# SERDES_10G0 register map
Vendor: Texas Instruments
Peripheral module from a debugger description file (folder J721S2).
Registers are 32-bit, read-write, reset 0x0 unless marked. A register's access mark holds for its fields unless they carry their own. Offsets are as the file gives them; lines under a group give offsets from that group; [hi:lo] are bit positions; {n}, {i} and the like mark numbered series; 'fields as' and 'values as' point back to an identical list; <NAME> marks a mode.

## SERDES_10G0 (part 1 of 5)
0x40 WIZ16B8M4CT2_CMN_SSM_BANDGAP_TMR__CMN_SSM_SM_CTRL reset 0x10000 — Startup state machine control register
  [20:16] CMN_SSM_BANDGAP_TMR_4_0 — Bandgap enable state timer value : Value used for the timer when the startup state machine is in the bandgap enable state. This timer delay is specified as the number of reference clocks to count. This value creates a delay of 40 nSec. Note, when exiting common suspend mode, a total of 1000 nSec is required for the bandgap to be enabled. This total delay is what is ultimately used to determine what the delay needs to be in the bandgap enable state. Of this total time, 960 nSec of this time is accounted for in the suspend recovery state. The remainder is accounted for here.
0x44 WIZ16B8M4CT2_CMN_SSM_BIAS_TMR reset 0x19 — Bias enable timer register
  [6:0] CMN_SSM_BIAS_TMR_6_0 — Bias enable state timer value : Value used for the timer when the startup state machine is in the bias enable state. This timer delay is specified as the number of reference clocks to count. This value creates a delay of 1 uSec.
0x50 WIZ16B8M4CT2_CMN_PLLSM0_PLLEN_TMR__CMN_PLLSM0_SM_CTRL reset 0x40000 — PLL 0 control state machine control register
  [19:16] CMN_PLLSM0_PLLEN_TMR_3_0 — PLL enable state timer value : Value used for the timer when the startup state machine is in the PLL enable state. This timer delay is specified as the number of reference clocks to count.
0x54 WIZ16B8M4CT2_CMN_PLLSM0_PLLVREF_TMR__CMN_PLLSM0_PLLPRE_TMR reset 0x32 — PLL 0 pre-charge timer register
  [7:0] CMN_PLLSM0_PLLPRE_TMR_7_0 — PLL pre-charge state timer value : Value used for the timer when the startup state machine is in the PLL pre-charge state. This timer delay is specified as the number of reference clocks to count. This value creates a delay of 2 uSec.
0x58 WIZ16B8M4CT2_CMN_PLLSM0_PLLCLKDIS_TMR__CMN_PLLSM0_PLLLOCK_TMR reset 0xD1 — PLL 0 lock delay timer register
  [9:0] CMN_PLLSM0_PLLLOCK_TMR_9_0 — PLL lock delay state timer value : Value used for the timer when the startup state machine is in the PLL lock delay state. This timer delay is specified as the number of reference clocks to count.
0x60 WIZ16B8M4CT2_CMN_PLLSM1_PLLEN_TMR__CMN_PLLSM1_SM_CTRL reset 0x40000 — PLL 1 control state machine control register
  [19:16] CMN_PLLSM1_PLLEN_TMR_3_0 — PLL enable state timer value : Value used for the timer when the startup state machine is in the PLL enable state. This timer delay is specified as the number of reference clocks to count.
0x64 WIZ16B8M4CT2_CMN_PLLSM1_PLLVREF_TMR__CMN_PLLSM1_PLLPRE_TMR reset 0x32 — PLL 1 pre-charge timer register
  [7:0] CMN_PLLSM1_PLLPRE_TMR_7_0 — PLL pre-charge state timer value : Value used for the timer when the startup state machine is in the PLL pre-charge state. This timer delay is specified as the number of reference clocks to count.
0x68 WIZ16B8M4CT2_CMN_PLLSM1_PLLCLKDIS_TMR__CMN_PLLSM1_PLLLOCK_TMR reset 0xD1 — PLL 1 lock delay timer register
  [9:0] CMN_PLLSM1_PLLLOCK_TMR_9_0 — PLL lock delay state timer value : Value used for the timer when the startup state machine is in the PLL lock delay state. This timer delay is specified as the number of reference clocks to count.
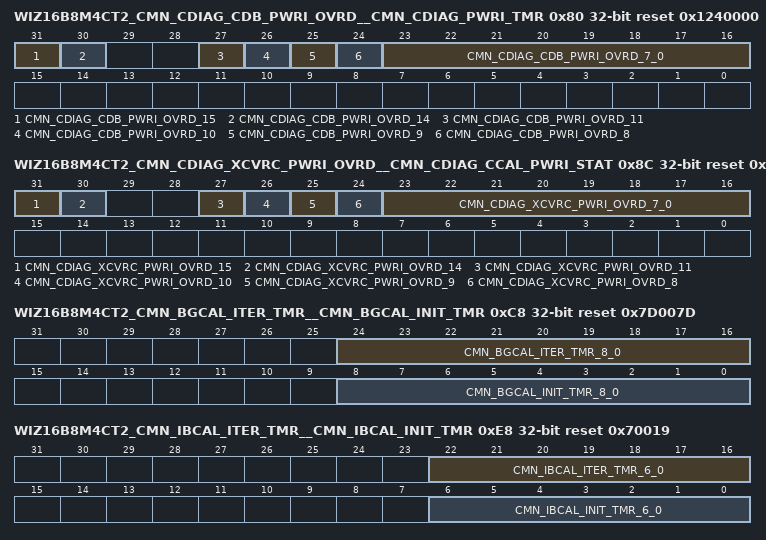
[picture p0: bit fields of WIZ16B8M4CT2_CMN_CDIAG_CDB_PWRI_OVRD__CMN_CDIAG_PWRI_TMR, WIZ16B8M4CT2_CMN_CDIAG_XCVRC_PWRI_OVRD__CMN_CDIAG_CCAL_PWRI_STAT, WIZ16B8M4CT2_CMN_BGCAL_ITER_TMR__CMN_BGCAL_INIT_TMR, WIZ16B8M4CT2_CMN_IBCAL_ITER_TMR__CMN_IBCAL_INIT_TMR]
0x80 WIZ16B8M4CT2_CMN_CDIAG_CDB_PWRI_OVRD__CMN_CDIAG_PWRI_TMR access per field reset 0x1240000 — Common power island control timer register
  [31] CMN_CDIAG_CDB_PWRI_OVRD_15 rw — Power island controller input override enable: When enabled, the power island control state machine input override bits in this register will drive the power island control state machine directly, and override any control from other state machines in the macro. Note that this bit must never change state in the same register write that any of the override bits it controls in this register are changed. 1'b0: Override disabled 1'b1: Override enabled
  [30] CMN_CDIAG_CDB_PWRI_OVRD_14 rw — Power island controller output override enable: When enabled, the power island control state machine output override bits in this register will drive the power island control state machine outputs, and override any control from power island control state machine. Note that this bit must never change state in the same register write that any of the override bits it controls in this register are changed. 1'b0: Override disabled 1'b1: Override enabled
  [27] CMN_CDIAG_CDB_PWRI_OVRD_11 rw — Power suspend request override: When enabled, this bit will override the power_suspend_req input of the power island control state machine. Note that, whenever changing the state of this bit, no other CDB register access should be initiated for 1 uSec, to keep the CDB clock off while the power island state change transition is in progress.
  [26] CMN_CDIAG_CDB_PWRI_OVRD_10 ro — Power suspend acknowledge: This is the current state of the power_suspend_ack output from the power island control state machine. Note that this bit will always be set to 1'b1 after the power island is enabled, as a function of the power island controller input override enable bit in this register.
  [25] CMN_CDIAG_CDB_PWRI_OVRD_9 rw — Power recover request override: When enabled, this bit will override the power_recover_req input of the power island control state machine. Note that, whenever changing the state of this bit, no other CDB register access should be initiated for 1 uSec, to keep the CDB clock off while the power island state change transition is in progress.
  [24] CMN_CDIAG_CDB_PWRI_OVRD_8 ro — Power recover acknowledge: This is the current state of the power_recover_ack output from the power island control state machine. Note that this bit will always be set to 1'b1 after the power island is enabled, as a function of the power island controller input override enable bit in this register.
  [23:16] CMN_CDIAG_CDB_PWRI_OVRD_7_0 rw — Power island controller output override: When enabled, the bits in this field will override the output signals from the power island control state machine. The following are the power island control state machine output signals, and the bits in this field that they are associated with. Bit 7: state_sandh Bit 6: state_ret_save Bit 5: state_ret_restore (active low) Bit 4: power_en_ph_1 Bit 3: power_en_ph_2 Bit 2: power_isolation Bit 1: power_por_reset_n Bit 0: power_rstr_reset_n The default value of the bits in this register are such that the power island is not forced to be switched on when the power island controller output override enable bit in this register is enabled. When using this register to switch this power island on and off, the bits in this field are required to change in a specific order with individual register writes. The writes must happen in the order specified below. 8'b00100100 : Power island is not being forced on 8'b10100100 8'b10110100 8'b10111100 8'b10111111 8'b10111011 8'b00111011 : Power island is being forced on 8'b10111011 8'b10111111 8'b11111111 8'b10111111 8'b10111110 8'b10100110 : Power island is being forced off, and in state retention 8'b10110110 8'b10111110 8'b10111111 8'b10011111 8'b10111111 8'b10111011 8'b00111011 : Power island is being forced on, with state restored Note: When using this output override option in conditions when the reference clock is off, the CDB registers on the power island will only be readable, and latency will be much longer. The reason for this is the reference clock is normally used to synchronize control functions associated with this power island. Therefore these control functions will not proceed as they would in normal operation. This results in writes not being capable, and reads completing under the control of the watchdog timer.
0x8C WIZ16B8M4CT2_CMN_CDIAG_XCVRC_PWRI_OVRD__CMN_CDIAG_CCAL_PWRI_STAT access per field reset 0x4240000 — Common common calibration power island control status register
  [31] CMN_CDIAG_XCVRC_PWRI_OVRD_15 rw — Power island controller input override enable: When enabled, the power island control state machine input override bits in this register will drive the power island control state machine directly, and override any control from other state machines in the macro. Note that this bit must never change state in the same register write that any of the override bits it controls in this register are changed. 1'b0: Override disabled 1'b1: Override enabled
  [30] CMN_CDIAG_XCVRC_PWRI_OVRD_14 rw — Power island controller output override enable: When enabled, the power island control state machine output override bits in this register will drive the power island control state machine outputs, and override any control from power island control state machine. Note that this bit must never change state in the same register write that any of the override bits it controls in this register are changed. 1'b0: Override disabled 1'b1: Override enabled
  [27] CMN_CDIAG_XCVRC_PWRI_OVRD_11 rw — Power suspend request override: When enabled, this bit will override the power_suspend_req input of the power island control state machine.
  [26] CMN_CDIAG_XCVRC_PWRI_OVRD_10 ro — Power suspend acknowledge: This is the current state of the power_suspend_ack output from the power island control state machine. Note that this bit will always be set to 1'b1 after the power island is enabled, as a function of the power island controller input override enable bit in this register.
  [25] CMN_CDIAG_XCVRC_PWRI_OVRD_9 rw — Power recover request override: When enabled, this bit will override the power_recover_req input of the power island control state machine.
  [24] CMN_CDIAG_XCVRC_PWRI_OVRD_8 ro — Power recover acknowledge: This is the current state of the power_recover_ack output from the power island control state machine. Note that this bit will always be set to 1'b1 after the power island is enabled, as a function of the power island controller input override enable bit in this register.
  [23:16] CMN_CDIAG_XCVRC_PWRI_OVRD_7_0 rw — Power island controller output override: When enabled, the bits in this field will override the output signals from the power island control state machine. The following are the power island control state machine output signals, and the bits in this field that they are associated with. Bit 7: state_sandh Bit 6: state_ret_save Bit 5: state_ret_restore (active low) Bit 4: power_en_ph_1 Bit 3: power_en_ph_2 Bit 2: power_isolation Bit 1: power_por_reset_n Bit 0: power_rstr_reset_n The default value of the bits in this register are such that the power island is not forced to be switched on when the power island controller output override enable bit in this register is enabled. When using this register to switch this power island on and off, the bits in this field are required to change in a specific order with individual register writes. The writes must happen in the order specified below. 8'b00100100 : Power island is not being forced on 8'b10100100 8'b10110100 8'b10111100 8'b10111111 8'b10111011 8'b00111011 : Power island is being forced on 8'b10111011 8'b10111111 8'b11111111 8'b10111111 8'b10111110 8'b10100110 : Power island is being forced off, and in state retention 8'b10110110 8'b10111110 8'b10111111 8'b10011111 8'b10111111 8'b10111011 8'b00111011 : Power island is being forced on, with state restored
0xC8 WIZ16B8M4CT2_CMN_BGCAL_ITER_TMR__CMN_BGCAL_INIT_TMR reset 0x7D007D — Bandgap calibration initialization timer register
  [24:16] CMN_BGCAL_ITER_TMR_8_0 — Iteration wait timer value: This is the number of cmn_ref_clk clocks to wait between when a value is placed on the bandgap calibration signals going to the analog, and when the comparator value coming from the analog circuits can be checked. Note that this results in the minimum number of cmn_ref_clk clocks required to wait 5 uSec. Note that this should never be set to a value of less than 3.
  [8:0] CMN_BGCAL_INIT_TMR_8_0 — Initialization wait timer value: This is the number of cmn_ref_clk clocks to wait between when the analog bandgap calibration circuits are enabled, and when the first values are placed on the bandgap calibration signals going to the analog. Note that this results in the minimum number of cmn_ref_clk clocks required to wait 5 uSec. Note that this should never be set to a value of less than 1.
0xE8 WIZ16B8M4CT2_CMN_IBCAL_ITER_TMR__CMN_IBCAL_INIT_TMR reset 0x70019 — External bias current calibration initialization timer register
  [22:16] CMN_IBCAL_ITER_TMR_6_0 — Iteration wait timer value: This is the number of cmn_ref_clk clocks to wait between when a value is placed on the calibration selection bus going to the analog, and when the comparator value coming from the analog circuits can be checked. Note that this should never be set to a value of less than 3.
  [6:0] CMN_IBCAL_INIT_TMR_6_0 — Initialization wait timer value: This is the number of cmn_ref_clk clocks to wait between when the analog calibration circuits are enabled, and when the first calibration selection value is placed on the calibration code bus, going to the analog. Note that this results in the minimum number of cmn_ref_clk clocks required to wait 1 uSec. Note that this should never be set to a value of less than 1.
0x104 WIZ16B8M4CT2_CMN_PLL0_VCOCAL_OVRD__CMN_PLL0_VCOCAL_TCTRL reset 0x4 — PLL 0 VCO calibration timer control register
  [2:0] CMN_PLL0_VCOCAL_TCTRL_2_0 — VCO calibration initial time scale control: This field specifies the calibration start time scaling factor applied to the VCO calibration when running the initial step size for the calibration code if not set to 1. Setting this value to a value other than 1 will reduce the calibration measurement time by the amount specified below. Then when the final calibration steps are made the full calibration time will be used to get the appropriate amount of resolution. 3'b000 : Div 1 3'b001 : Div 2 3'b010 : Div 4 3'b011 : Div 8 3'b100 : Div 16 3'b101 : Div 32 3'b110 : Div 64 3'b111 : Div 128
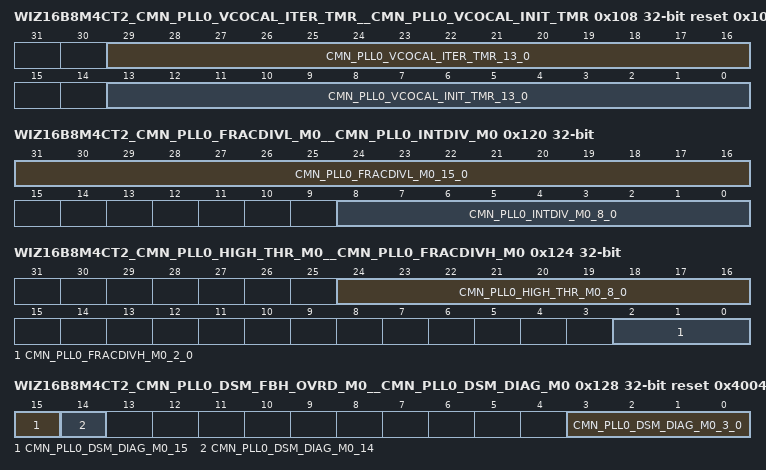
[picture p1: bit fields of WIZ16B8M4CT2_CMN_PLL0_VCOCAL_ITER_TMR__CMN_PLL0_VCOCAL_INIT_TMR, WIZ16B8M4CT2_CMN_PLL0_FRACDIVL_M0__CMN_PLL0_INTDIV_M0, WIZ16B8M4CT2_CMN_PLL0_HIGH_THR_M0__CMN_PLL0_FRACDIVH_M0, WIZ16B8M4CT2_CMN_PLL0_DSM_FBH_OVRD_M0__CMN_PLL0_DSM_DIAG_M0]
0x108 WIZ16B8M4CT2_CMN_PLL0_VCOCAL_ITER_TMR__CMN_PLL0_VCOCAL_INIT_TMR reset 0x1003E8 — PLL 0 VCO calibration initialization timer register
  [29:16] CMN_PLL0_VCOCAL_ITER_TMR_13_0 — Iteration wait timer value: This is the number of clocks to wait between when a calibration code is driven to the analog, and when the clock rates are measured.
  [13:0] CMN_PLL0_VCOCAL_INIT_TMR_13_0 — Initialization wait timer value: This is the number of clocks to wait between when the analog VCO calibration circuits are enabled, and when the first calibration code is driven to the analog. Note that this results in the minimum number of cmn_ref_clk clocks required to wait 10 uSec.
0x10C WIZ16B8M4CT2_CMN_PLL0_VCOCAL_REFTIM_START reset 0xC5F — PLL 0 VCO calibration reference clock timer start value register
  [13:0] CMN_PLL0_VCOCAL_REFTIM_START_13_0 — PLL VCO calibration reference clock timer start value : This is the value that is loaded into the reference clock timer as the starting point for that timer, when running VCO calibration. The value in this field must correspond to a time that is approximately one full spread spectrum cycle long (31.67 uSec) Note that the actual number of clocks counted is one larger than what is specified by this field.
0x110 WIZ16B8M4CT2_CMN_PLL0_VCOCAL_PLLCNT_START reset 0xC5F — PLL 0 VCO calibration PLL clock counter start value register
  [13:0] CMN_PLL0_VCOCAL_PLLCNT_START_13_0 — PLL VCO calibration PLL clock counter start value : This is the value that is loaded into the PLL clock counter as the starting point for that counter, when running VCO calibration. When programming this register, it is important to understand how the frequency of the cmnda_pll0_fb_divider_clk is calculated relative to the reference clock. This is described in section 10.4 Dual VCO PLL on page 420. Note that the actual number of clocks counted is one larger than what is specified by this field.
0x120 WIZ16B8M4CT2_CMN_PLL0_FRACDIVL_M0__CMN_PLL0_INTDIV_M0 — PLL 0 feedback divider integer register mode 0
  [31:16] CMN_PLL0_FRACDIVL_M0_15_0 — pll_fb_div_fractional: Value of the pll_fb_div_fractional[15:0] signal.
  [8:0] CMN_PLL0_INTDIV_M0_8_0 — pll_fb_div_integer value: Value of the pll_fb_div_integer signal.
0x124 WIZ16B8M4CT2_CMN_PLL0_HIGH_THR_M0__CMN_PLL0_FRACDIVH_M0 — PLL 0 feedback divider fractional high register mode 0
  [24:16] CMN_PLL0_HIGH_THR_M0_8_0 — pll_fb_div_high_theshold: Value of the pll_fb_div_high_threshold signal. The value of this register should be 2/3 the value of the combined integer and fractional divider values, and rounded up to the next even number.
  [2:0] CMN_PLL0_FRACDIVH_M0_2_0 — pll_fb_div_fractional: Value of the pll_fb_div_fractional[18:16] signal.
0x128 WIZ16B8M4CT2_CMN_PLL0_DSM_FBH_OVRD_M0__CMN_PLL0_DSM_DIAG_M0 reset 0x4004 — PLL 0 delta sigma modulator diagnostics register mode 0
  [15] CMN_PLL0_DSM_DIAG_M0_15 — Delta sigma bypass enable: When set to 1'b1, the delta sigma modulator will be bypassed, and the output will be the value specified for the internal pll_fb_div_integer signal.
  [14] CMN_PLL0_DSM_DIAG_M0_14 — PLL feedback divider override enable : When active (1'b1), the feedback divider low and high override values in the PLL 0 delta sigma modulator feedback divider value high override register mode 0 on page 114 and PLL 0 delta sigma modulator feedback divider value low override register mode 0 on page 114 registers will be used to override the feedback divider values driven to the analog.
  [3:0] CMN_PLL0_DSM_DIAG_M0_3_0 — PLL feedback divider latency adjustment: This signal specifies a value to be subtracted from the feedback divider settings before they are output on the cmnda_pll0_fb_div_high and cmnda_pll0_fb_div_low signals.
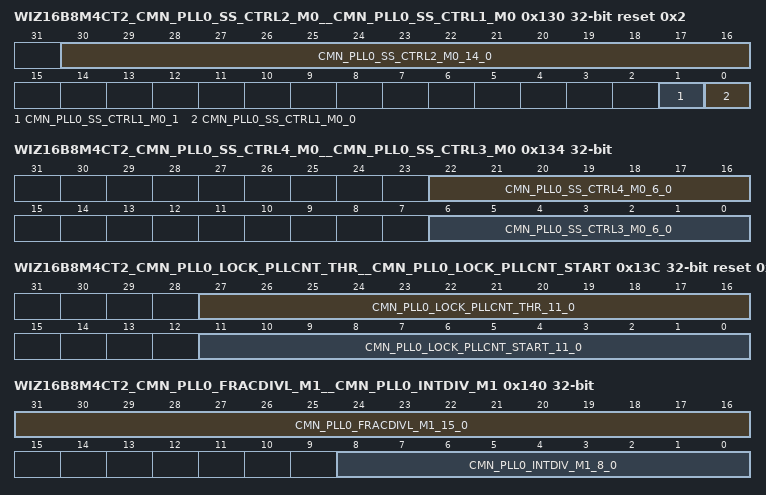
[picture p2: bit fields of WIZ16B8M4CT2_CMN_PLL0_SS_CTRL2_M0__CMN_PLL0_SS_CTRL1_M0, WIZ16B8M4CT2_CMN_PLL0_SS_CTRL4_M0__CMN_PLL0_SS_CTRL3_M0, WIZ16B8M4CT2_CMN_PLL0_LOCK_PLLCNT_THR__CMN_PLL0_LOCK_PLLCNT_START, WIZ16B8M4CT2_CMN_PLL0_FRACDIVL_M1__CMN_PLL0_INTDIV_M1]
0x130 WIZ16B8M4CT2_CMN_PLL0_SS_CTRL2_M0__CMN_PLL0_SS_CTRL1_M0 reset 0x2 — PLL 0 spread spectrum control register 1 mode 0
  [30:16] CMN_PLL0_SS_CTRL2_M0_14_0 — Amplitude step size: Value of the amplitude_step_size pin on the spread spectrum waveform generator. Note that this field should not be set to 0 when spread spectrum is enabled.
  [1] CMN_PLL0_SS_CTRL1_M0_1 — Spread spectrum waveform generator disable: Setting this bit to a 1'b1 will disable the spread spectrum waveform generator.
  [0] CMN_PLL0_SS_CTRL1_M0_0 — Spread spectrum enable during VCO calibration : Setting this bit to a 1'b1 will enable the spread spectrum function while VCO calibration is taking place.
0x134 WIZ16B8M4CT2_CMN_PLL0_SS_CTRL4_M0__CMN_PLL0_SS_CTRL3_M0 — PLL 0 spread spectrum control register 3 mode 0
  [22:16] CMN_PLL0_SS_CTRL4_M0_6_0 — Time step size: Value for the time_step_size pin on the spread spectrum waveform generator. Note that this field should not be set to 0 when spread spectrum is enabled.
  [6:0] CMN_PLL0_SS_CTRL3_M0_6_0 — Number of steps: Value of the num_steps pin on the spread spectrum waveform generator. Note that this field should not be set to 0 when spread spectrum is enabled.
0x138 WIZ16B8M4CT2_CMN_PLL0_LOCK_REFCNT_IDLE__CMN_PLL0_LOCK_REFCNT_START reset 0xC8 — PLL 0 lock reference counter start value register
  [11:0] CMN_PLL0_LOCK_REFCNT_START_11_0 — PLL lock reference counter start value : This is the value that is loaded into the PLL lock detect reference counter as the starting point for that counter, when checking for PLL lock. Note that the value required here is a function of the PLL feedback divider clock mode and the reference clock frequency. Overview information in regards to this can be found in section 4.2 Reference Clock Related Clocking and Reset on page 296 and section 4.9 Reference Clock Related Clock Rate Summary on page 324. The following bullet points specify the required time the value in this register is required to generate. By default, the value in this register is set for FBR mode with a 100 MHz reference clock. FBR mode and reference clock frequency greater than or equal to 100 MHz: 2 uSec FBR mode and reference clock frequency less than 100 MHz: 8 uSec DR mode: 800 nSec
0x13C WIZ16B8M4CT2_CMN_PLL0_LOCK_PLLCNT_THR__CMN_PLL0_LOCK_PLLCNT_START reset 0x300C8 — PLL 0 lock PLL counter start value register
  [27:16] CMN_PLL0_LOCK_PLLCNT_THR_11_0 — PLL lock counter threshold value : This is the value used by the PLL lock detection logic to determine if the PLL has locked. If the two counters in the PLL lock detection logic differ by less than this value, the PLL is considered locked.
  [11:0] CMN_PLL0_LOCK_PLLCNT_START_11_0 — PLL lock PLL counter start value : This is the value that is loaded into the PLL lock detect PLL counter as the starting point for that counter, when checking for PLL lock. The value is the number of PLL feedback divider clock edges that are expected during the time specified by the PLL 0 lock reference counter start value register on page 112. When programming this register, it is important to understand how the frequency of the cmnda_pll0_fb_divider_clk is calculated relative to the reference clock. This is described in section 10.4 Dual VCO PLL on page 420.
0x140 WIZ16B8M4CT2_CMN_PLL0_FRACDIVL_M1__CMN_PLL0_INTDIV_M1 — PLL 0 feedback divider integer register mode 1
  [31:16] CMN_PLL0_FRACDIVL_M1_15_0 — pll_fb_div_fractional: Value of the pll_fb_div_fractional[15:0] signal.
  [8:0] CMN_PLL0_INTDIV_M1_8_0 — pll_fb_div_integer value: Value of the pll_fb_div_integer signal.
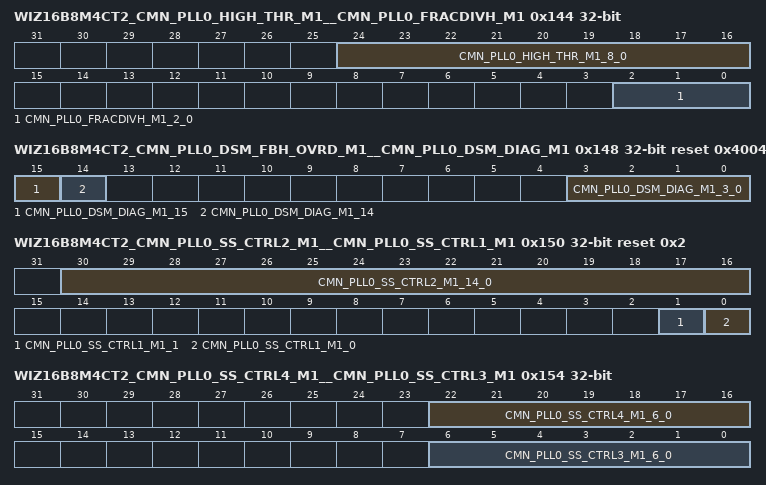
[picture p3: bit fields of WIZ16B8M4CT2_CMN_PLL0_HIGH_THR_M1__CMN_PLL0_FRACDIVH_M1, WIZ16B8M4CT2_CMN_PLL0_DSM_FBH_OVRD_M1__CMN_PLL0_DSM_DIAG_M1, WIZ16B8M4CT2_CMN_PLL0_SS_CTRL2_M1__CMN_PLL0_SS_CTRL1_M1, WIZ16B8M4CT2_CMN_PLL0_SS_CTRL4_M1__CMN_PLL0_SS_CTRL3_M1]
0x144 WIZ16B8M4CT2_CMN_PLL0_HIGH_THR_M1__CMN_PLL0_FRACDIVH_M1 — PLL 0 feedback divider fractional high register mode 1
  [24:16] CMN_PLL0_HIGH_THR_M1_8_0 — pll_fb_div_high_theshold: Value of the pll_fb_div_high_threshold signal. The value of this register should be 2/3 the value of the combined integer and fractional divider values, and rounded up to the next even number.
  [2:0] CMN_PLL0_FRACDIVH_M1_2_0 — pll_fb_div_fractional: Value of the pll_fb_div_fractional[18:16] signal.
0x148 WIZ16B8M4CT2_CMN_PLL0_DSM_FBH_OVRD_M1__CMN_PLL0_DSM_DIAG_M1 reset 0x4004 — PLL 0 delta sigma modulator diagnostics register mode 1
  [15] CMN_PLL0_DSM_DIAG_M1_15 — Delta sigma bypass enable: When set to 1'b1, the delta sigma modulator will be bypassed, and the output will be the value specified for the internal pll_fb_div_integer signal.
  [14] CMN_PLL0_DSM_DIAG_M1_14 — PLL feedback divider override enable : When active (1'b1), the feedback divider low and high override values in the PLL 0 delta sigma modulator feedback divider value high override register mode 0 on page 114 and PLL 0 delta sigma modulator feedback divider value low override register mode 0 on page 114 registers will be used to override the feedback divider values driven to the analog.
  [3:0] CMN_PLL0_DSM_DIAG_M1_3_0 — PLL feedback divider latency adjustment: This signal specifies a value to be subtracted from the feedback divider settings before they are output on the cmnda_pll0_fb_div_high and cmnda_pll0_fb_div_low signals.
0x150 WIZ16B8M4CT2_CMN_PLL0_SS_CTRL2_M1__CMN_PLL0_SS_CTRL1_M1 reset 0x2 — PLL 0 spread spectrum control register 1 mode 1
  [30:16] CMN_PLL0_SS_CTRL2_M1_14_0 — Amplitude step size: Value of the amplitude_step_size pin on the spread spectrum waveform generator. Note that this field should not be set to 0 when spread spectrum is enabled.
  [1] CMN_PLL0_SS_CTRL1_M1_1 — Spread spectrum waveform generator disable: Setting this bit to a 1'b1 will disable the spread spectrum waveform generator.
  [0] CMN_PLL0_SS_CTRL1_M1_0 — Spread spectrum enable during VCO calibration : Setting this bit to a 1'b1 will enable the spread spectrum function while VCO calibration is taking place.
0x154 WIZ16B8M4CT2_CMN_PLL0_SS_CTRL4_M1__CMN_PLL0_SS_CTRL3_M1 — PLL 0 spread spectrum control register 3 mode 1
  [22:16] CMN_PLL0_SS_CTRL4_M1_6_0 — Time step size: Value for the time_step_size pin on the spread spectrum waveform generator. Note that this field should not be set to 0 when spread spectrum is enabled.
  [6:0] CMN_PLL0_SS_CTRL3_M1_6_0 — Number of steps: Value of the num_steps pin on the spread spectrum waveform generator. Note that this field should not be set to 0 when spread spectrum is enabled.
0x184 WIZ16B8M4CT2_CMN_PLL1_VCOCAL_OVRD__CMN_PLL1_VCOCAL_TCTRL reset 0x4 — PLL 1 VCO calibration timer control register
  [2:0] CMN_PLL1_VCOCAL_TCTRL_2_0 — VCO calibration initial time scale control: This field specifies the calibration start time scaling factor applied to the VCO calibration when running the initial step size for the calibration code if not set to 1. Setting this value to a value other than 1 will reduce the calibration measurement time by the amount specified below. Then when the final calibration steps are made the full calibration time will be used to get the appropriate amount of resolution. 3'b000 : Div 1 3'b001 : Div 2 3'b010 : Div 4 3'b011 : Div 8 3'b100 : Div 16 3'b101 : Div 32 3'b110 : Div 64 3'b111 : Div 128
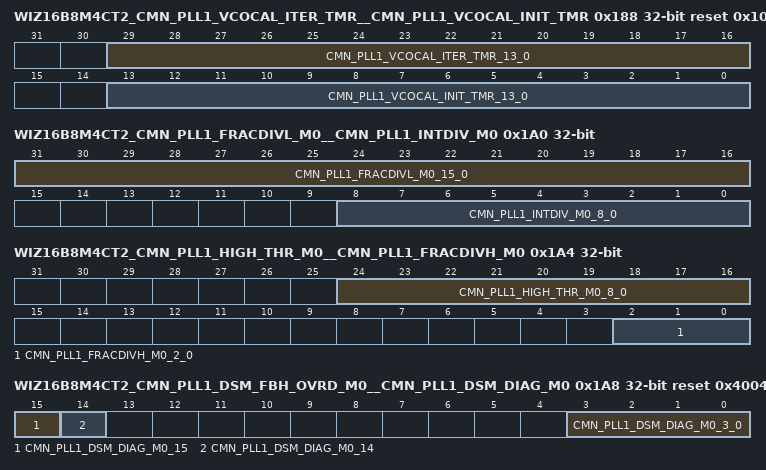
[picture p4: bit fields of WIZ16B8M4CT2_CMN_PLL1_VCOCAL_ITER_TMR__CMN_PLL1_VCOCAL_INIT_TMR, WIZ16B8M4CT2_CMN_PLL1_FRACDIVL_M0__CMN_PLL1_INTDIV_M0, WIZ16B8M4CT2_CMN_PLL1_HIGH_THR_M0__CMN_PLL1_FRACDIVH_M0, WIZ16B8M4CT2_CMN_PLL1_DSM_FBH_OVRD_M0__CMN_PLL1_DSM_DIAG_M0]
0x188 WIZ16B8M4CT2_CMN_PLL1_VCOCAL_ITER_TMR__CMN_PLL1_VCOCAL_INIT_TMR reset 0x1003E8 — PLL 1 VCO calibration initialization timer register
  [29:16] CMN_PLL1_VCOCAL_ITER_TMR_13_0 — Iteration wait timer value: This is the number of clocks to wait between when a calibration code is driven to the analog, and when the clock rates are measured.
  [13:0] CMN_PLL1_VCOCAL_INIT_TMR_13_0 — Initialization wait timer value: This is the number of clocks to wait between when the analog VCO calibration circuits are enabled, and when the first calibration code is driven to the analog. Note that the reset value for this field corresponds to a time of 10 uSec.
0x18C WIZ16B8M4CT2_CMN_PLL1_VCOCAL_REFTIM_START reset 0xC5F — PLL 1 VCO calibration reference clock timer start value register
  [13:0] CMN_PLL1_VCOCAL_REFTIM_START_13_0 — PLL VCO calibration reference clock timer start value : This is the value that is loaded into the reference clock timer as the starting point for that timer, when running VCO calibration. The value in this field must correspond to a time that is approximately one full spread spectrum cycle long (31.67 uSec) Note that the actual number of clocks counted is one larger than what is specified by this field.
0x190 WIZ16B8M4CT2_CMN_PLL1_VCOCAL_PLLCNT_START reset 0xC5F — PLL 1 VCO calibration PLL clock counter start value register
  [13:0] CMN_PLL1_VCOCAL_PLLCNT_START_13_0 — PLL VCO calibration PLL clock counter start value : This is the value that is loaded into the PLL clock counter as the starting point for that counter, when running VCO calibration. When programming this register, it is important to understand how the frequency of the cmnda_pll0_fb_divider_clk is calculated relative to the reference clock. This is described in section 10.4 Dual VCO PLL on page 420. Note that the actual number of clocks counted is one larger than what is specified by this field.
0x1A0 WIZ16B8M4CT2_CMN_PLL1_FRACDIVL_M0__CMN_PLL1_INTDIV_M0 — PLL 1 feedback divider integer register mode 0
  [31:16] CMN_PLL1_FRACDIVL_M0_15_0 — pll_fb_div_fractional: Value of the pll_fb_div_fractional[15:0] signal.
  [8:0] CMN_PLL1_INTDIV_M0_8_0 — pll_fb_div_integer value: Value of the pll_fb_div_integer signal.
0x1A4 WIZ16B8M4CT2_CMN_PLL1_HIGH_THR_M0__CMN_PLL1_FRACDIVH_M0 — PLL 1 feedback divider fractional high register mode 0
  [24:16] CMN_PLL1_HIGH_THR_M0_8_0 — pll_fb_div_high_theshold: Value of the pll_fb_div_high_threshold signal. The value of this register should be 2/3 the value of the combined integer and fractional divider values, and rounded up to the next even number.
  [2:0] CMN_PLL1_FRACDIVH_M0_2_0 — pll_fb_div_fractional: Value of the pll_fb_div_fractional[18:16] signal.
0x1A8 WIZ16B8M4CT2_CMN_PLL1_DSM_FBH_OVRD_M0__CMN_PLL1_DSM_DIAG_M0 reset 0x4004 — PLL 1 delta sigma modulator diagnostics register mode 0
  [15] CMN_PLL1_DSM_DIAG_M0_15 — Delta sigma bypass enable: When set to 1'b1, the delta sigma modulator will be bypassed, and the output will be the value specified for the internal pll_fb_div_integer signal.
  [14] CMN_PLL1_DSM_DIAG_M0_14 — PLL feedback divider override enable : When active (1'b1), the feedback divider low and high override values in the PLL 1 delta sigma modulator feedback divider value high override register mode 0 on page 123 and PLL 1 delta sigma modulator feedback divider value low override register mode 0 on page 123 registers will be used to override the feedback divider values driven to the analog.
  [3:0] CMN_PLL1_DSM_DIAG_M0_3_0 — PLL feedback divider latency adjustment: This signal specifies a value to be subtracted from the feedback divider settings before they are output on the cmnda_pll1_fb_div_high and cmnda_pll1_fb_div_low signals.
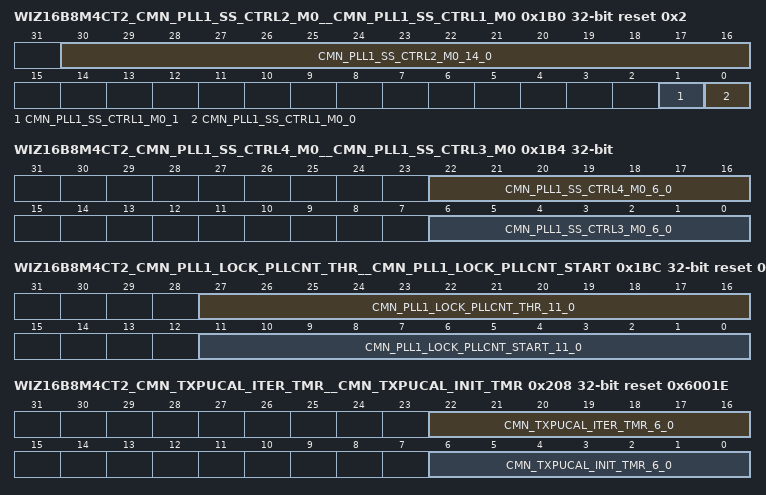
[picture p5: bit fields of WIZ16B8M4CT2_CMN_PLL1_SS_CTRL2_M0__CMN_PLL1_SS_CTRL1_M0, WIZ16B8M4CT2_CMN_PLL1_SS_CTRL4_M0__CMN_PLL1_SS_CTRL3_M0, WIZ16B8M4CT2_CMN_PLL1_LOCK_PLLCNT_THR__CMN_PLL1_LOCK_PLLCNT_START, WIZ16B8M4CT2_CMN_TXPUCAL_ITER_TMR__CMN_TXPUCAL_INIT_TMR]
0x1B0 WIZ16B8M4CT2_CMN_PLL1_SS_CTRL2_M0__CMN_PLL1_SS_CTRL1_M0 reset 0x2 — PLL 1 spread spectrum control register 1 mode 0
  [30:16] CMN_PLL1_SS_CTRL2_M0_14_0 — Amplitude step size: Value of the amplitude_step_size pin on the spread spectrum waveform generator. Note that this field should not be set to 0 when spread spectrum is enabled.
  [1] CMN_PLL1_SS_CTRL1_M0_1 — Spread spectrum waveform generator disable: Setting this bit to a 1'b1 will disable the spread spectrum waveform generator.
  [0] CMN_PLL1_SS_CTRL1_M0_0 — Spread spectrum enable during VCO calibration : Setting this bit to a 1'b1 will enable the spread spectrum function while VCO calibration is taking place.
0x1B4 WIZ16B8M4CT2_CMN_PLL1_SS_CTRL4_M0__CMN_PLL1_SS_CTRL3_M0 — PLL 1 spread spectrum control register 3 mode 0
  [22:16] CMN_PLL1_SS_CTRL4_M0_6_0 — Time step size: Value for the time_step_size pin on the spread spectrum waveform generator. Note that this field should not be set to 0 when spread spectrum is enabled.
  [6:0] CMN_PLL1_SS_CTRL3_M0_6_0 — Number of steps: Value of the num_steps pin on the spread spectrum waveform generator. Note that this field should not be set to 0 when spread spectrum is enabled.
0x1B8 WIZ16B8M4CT2_CMN_PLL1_LOCK_REFCNT_IDLE__CMN_PLL1_LOCK_REFCNT_START reset 0xC8 — PLL 1 lock reference counter start value register
  [11:0] CMN_PLL1_LOCK_REFCNT_START_11_0 — PLL lock reference counter start value : This is the value that is loaded into the PLL lock detect reference counter as the starting point for that counter, when checking for PLL lock. Note that the value required here is a function of the PLL feedback divider clock mode and the reference clock frequency. Overview information in regards to this can be found in section 4.2 Reference Clock Related Clocking and Reset on page 296 and section 4.9 Reference Clock Related Clock Rate Summary on page 324. The following bullet points specify the required time the value in this register is required to generate. By default, the value in this register is set for FBR mode with a 100 MHz reference clock. FBR mode and reference clock frequency greater than or equal to 100 MHz: 2 uSec FBR mode and reference clock frequency less than 100 MHz: 8 uSec DR mode: 800 nSec
0x1BC WIZ16B8M4CT2_CMN_PLL1_LOCK_PLLCNT_THR__CMN_PLL1_LOCK_PLLCNT_START reset 0x300C8 — PLL 1 lock PLL counter start value register
  [27:16] CMN_PLL1_LOCK_PLLCNT_THR_11_0 — PLL lock counter threshold value : This is the value used by the PLL lock detection logic to determine if the PLL has locked. If the two counters in the PLL lock detection logic differ by less than this value, the PLL is considered locked.
  [11:0] CMN_PLL1_LOCK_PLLCNT_START_11_0 — PLL lock PLL counter start value : This is the value that is loaded into the PLL lock detect PLL counter as the starting point for that counter, when checking for PLL lock. The value is the number of PLL feedback divider clock edges that are expected during the time specified by the PLL 0 lock reference counter start value register on page 112. When programming this register, it is important to understand how the frequency of the cmnda_pll0_fb_divider_clk is calculated relative to the reference clock. This is described in section 10.4 Dual VCO PLL on page 420.
0x204 WIZ16B8M4CT2_CMN_TXPUCAL_TUNE__CMN_TXPUCAL_START — TX pull-up resistor calibration start register
  [22:16] CMN_TXPUCAL_TUNE_6_0 — Resistor calibration tune value: The value of this field is added to the automatically calibrated code, or the override code if override is enabled. Note that this value is a twos complement value, so the calibrated code can be increased or decreased.
0x208 WIZ16B8M4CT2_CMN_TXPUCAL_ITER_TMR__CMN_TXPUCAL_INIT_TMR reset 0x6001E — TX pull-up resistor calibration initialization timer register
  [22:16] CMN_TXPUCAL_ITER_TMR_6_0 — Iteration wait timer value: This is the number of cmn_ref_clk clocks to wait between when a value is placed on the resistor selection bus going to the analog, and when the comparator value coming from the analog circuits can be checked. Note that this results in the minimum number of cmn_ref_clk clocks required to wait 240 nSec. Note that this should never be set to a value of less than 3.
  [6:0] CMN_TXPUCAL_INIT_TMR_6_0 — Initialization wait timer value: This is the number of cmn_ref_clk clocks to wait between when the analog resistor calibration circuits are enabled, and when the first resistor selection values are placed on the resistor selection bus, going to the analog. Note that this results in the minimum number of cmn_ref_clk clocks required to wait 1.2 uSec. Note that this should never be set to a value of less than 1.
0x214 WIZ16B8M4CT2_CMN_TXPDCAL_TUNE__CMN_TXPDCAL_START — TX pull-down resistor calibration start register
  [22:16] CMN_TXPDCAL_TUNE_6_0 — Resistor calibration tune value: The value of this field is added to the automatically calibrated code, or the override code if override is enabled. Note that this value is a twos complement value, so the calibrated code can be increased or decreased.
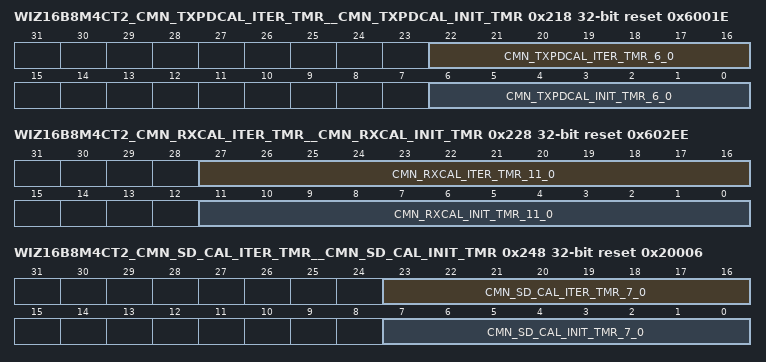
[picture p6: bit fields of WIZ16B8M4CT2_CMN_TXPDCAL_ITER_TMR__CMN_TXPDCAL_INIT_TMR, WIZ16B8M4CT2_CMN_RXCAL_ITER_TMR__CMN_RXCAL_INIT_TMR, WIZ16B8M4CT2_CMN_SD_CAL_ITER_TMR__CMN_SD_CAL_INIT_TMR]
0x218 WIZ16B8M4CT2_CMN_TXPDCAL_ITER_TMR__CMN_TXPDCAL_INIT_TMR reset 0x6001E — TX pull-down resistor calibration initialization timer register
  [22:16] CMN_TXPDCAL_ITER_TMR_6_0 — Iteration wait timer value: This is the number of cmn_ref_clk clocks to wait between when a value is placed on the resistor selection bus going to the analog, and when the comparator value coming from the analog circuits can be checked. Note that this results in the minimum number of cmn_ref_clk clocks required to wait 240 nSec. Note that this should never be set to a value of less than 3.
  [6:0] CMN_TXPDCAL_INIT_TMR_6_0 — Initialization wait timer value: This is the number of cmn_ref_clk clocks to wait between when the analog resistor calibration circuits are enabled, and when the first resistor selection values are placed on the resistor selection bus, going to the analog. Note that this results in the minimum number of cmn_ref_clk clocks required to wait 1.2 uSec. Note that this should never be set to a value of less than 1.
0x228 WIZ16B8M4CT2_CMN_RXCAL_ITER_TMR__CMN_RXCAL_INIT_TMR reset 0x602EE — RX resistor calibration initialization timer register
  [27:16] CMN_RXCAL_ITER_TMR_11_0 — Iteration wait timer value: This is the number of cmn_ref_clk clocks to wait between when a value is placed on the resistor selection bus going to the analog, and when the comparator value coming from the analog circuits can be checked. Note that this results in the minimum number of cmn_ref_clk clocks required to wait 240 nSec. Note that this should never be set to a value of less than 3.
  [11:0] CMN_RXCAL_INIT_TMR_11_0 — Initialization wait timer value: This is the number of cmn_ref_clk clocks to wait between when the analog resistor calibration circuits are enabled, and when the first resistor selection values are placed on the resistor selection bus, going to the analog. Note that this results in the minimum number of cmn_ref_clk clocks required to wait 30 uSec. Note that this should never be set to a value of less than 1.
0x248 WIZ16B8M4CT2_CMN_SD_CAL_ITER_TMR__CMN_SD_CAL_INIT_TMR reset 0x20006 — Signal detect clock calibration initialization timer register
  [23:16] CMN_SD_CAL_ITER_TMR_7_0 — Iteration wait timer value: This is the number of clocks to wait between when a calibration code is driven to the analog, and when the clock rates are measured. Note that this results in the minimum number of cmn_ref_clk clocks required to wait 80 nSec.
  [7:0] CMN_SD_CAL_INIT_TMR_7_0 — Initialization wait timer value: This is the number of clocks to wait between when the analog calibration circuits are enabled, and when the first calibration code is driven to the analog. Note that this results in the minimum number of cmn_ref_clk clocks required to wait 80 nSec for the analog plus four reference clocks for the digital clock gating to be enabled.
0x24C WIZ16B8M4CT2_CMN_SD_CAL_REFTIM_START reset 0xE — Signal detect clock calibration reference clock timer start value register
  [7:0] CMN_SD_CAL_REFTIM_START_7_0 — Calibration reference clock timer start value : This is the value that is loaded into the reference clock timer as the starting point for that timer, when running calibration. Note that the actual number of clocks counted is one larger than what is specified by this field.
0x250 WIZ16B8M4CT2_CMN_SD_CAL_PLLCNT_START reset 0x12B — Signal detect clock calibration PLL clock counter start value register
  [9:0] CMN_SD_CAL_PLLCNT_START_9_0 — Calibration feedback clock counter start value : This is the value that is loaded into the PLL clock counter as the starting point for that counter, when running calibration. Note that the actual number of clocks counted is one larger than what is specified by this field.
